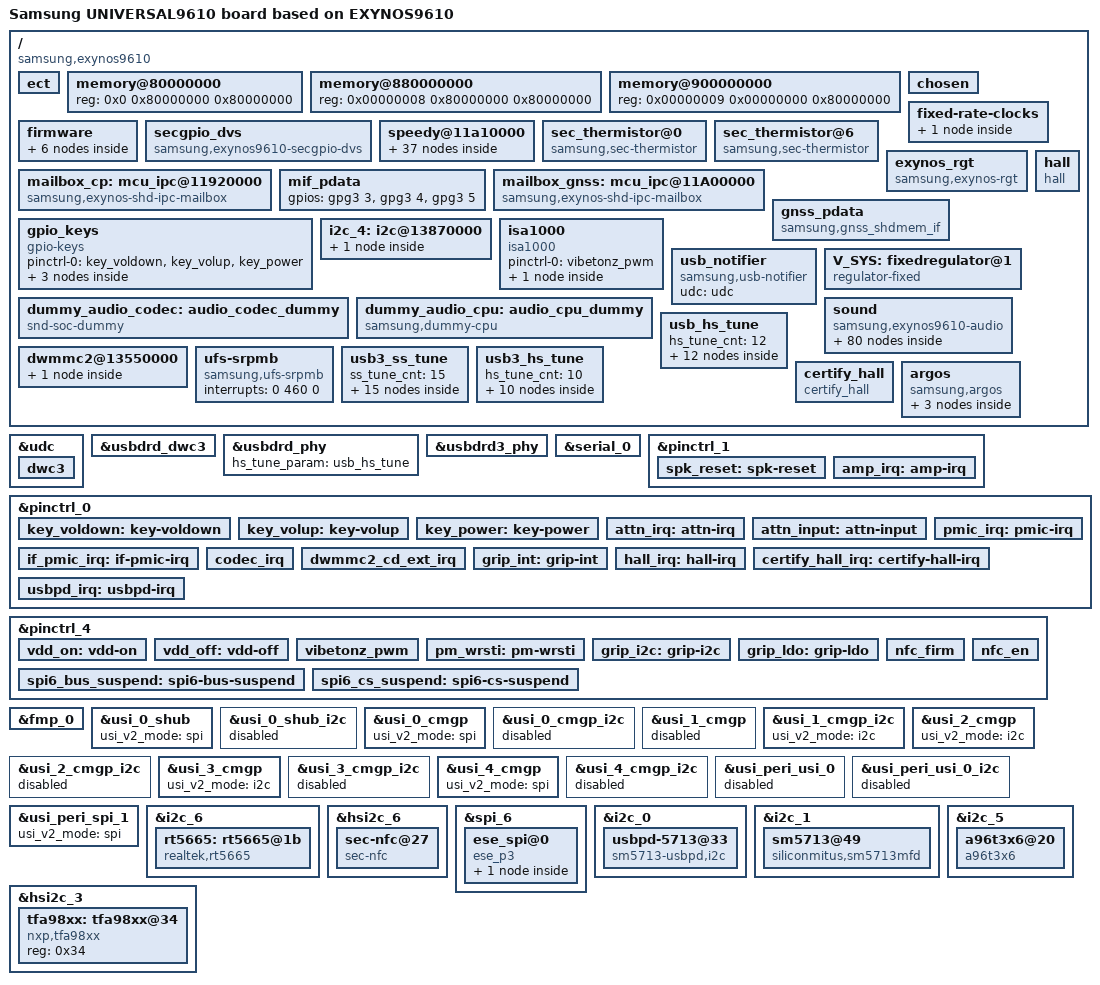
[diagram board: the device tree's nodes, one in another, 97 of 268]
/*
 * SAMSUNG EXYNOS9610 board device tree source
 *
 * Copyright (c) 2018 Samsung Electronics Co., Ltd.
 *		http://www.samsung.com
 *
 * This program is free software; you can redistribute it and/or modify
 * it under the terms of the GNU General Public License version 2 as
 * published by the Free Software Foundation.
 */

/dts-v1/;
/plugin/;

#include "battery_data_voguelte_common.dtsi"
#include <dt-bindings/camera/fimc_is.h>
#include <dt-bindings/clock/exynos9610.h>
#include "modem-s337ap-sipc-pdata.dtsi"
#include "display-lcd_vogue_common.dtsi"
#include "exynos9610-voguelte_camera.dtsi"
#include "exynos9610-inputbooster.dtsi"

/ {
	compatible = "samsung,exynos9610", "samsung,UNIVERSAL9610";

	fragment@model {
		target-path = "/";
		__overlay__ {
			#address-cells = <2>;
			#size-cells = <1>;
			model = "Samsung UNIVERSAL9610 board based on EXYNOS9610";

			ect {
				parameter_address = <0xA0000000>;
				parameter_size = <0x3A000>;
			};

			memory@80000000 {
				device_type = "memory";
				reg = <0x0 0x80000000 0x80000000>;
			};

			memory@880000000 {
				device_type = "memory";
				reg = <0x00000008 0x80000000 0x80000000>;
			};

			memory@900000000 {
				device_type = "memory";
				reg = <0x00000009 0x00000000 0x80000000>;
			};

			chosen {
				bootargs = "console=ram skip_initramfs rootwait ro init=/init clk_ignore_unused bcm_setup=0xffffff80f8e00000 androidboot.hardware=exynos9610 androidboot.selinux=permissive androidboot.debug_level=0x4948 firmware_class.path=/vendor/firmware ecd_setup=disable reserve-fimc=0xffffff80f9fe0000 pmic_info=0x3 epx_activate=true";
				linux,initrd-start = <0x84000000>;
				linux,initrd-end = <0x841FFFFF>;
			};

			fixed-rate-clocks {
				oscclk {
					compatible = "samsung,exynos9610-oscclk";
					clock-frequency = <26000000>;
				};
			};

			firmware {
				android {
					compatible = "android,firmware";
					vbmeta {
						compatible = "android,vbmeta";
						parts = "vbmeta,boot,system,vendor";
					};
					fstab {
						compatible = "android,fstab";
						system {
							compatible = "android,system";
							dev = "/dev/block/platform/13520000.ufs/by-name/system";
							type = "ext4";
							mnt_flags = "ro";
							fsmgr_flags = "wait, avb";
							status = "disabled";
						};
						vendor {
							compatible = "android,vendor";
							dev = "/dev/block/platform/13520000.ufs/by-name/vendor";
							type = "ext4";
							mnt_flags = "ro";
							fsmgr_flags = "wait, avb";
							status = "okay";
						};
						product {
							compatible = "android,product";
							dev = "/dev/block/platform/13520000.ufs/by-name/product";
							type = "ext4";
							mnt_flags = "ro";
							fsmgr_flags = "wait";
						};
					};
				};
			};

			secgpio_dvs {
				compatible = "samsung,exynos9610-secgpio-dvs";
				status = "okay";
			};

			speedy@11a10000 {
				#address-cells = <1>;
				#size-cells = <0>;
				status = "okay";
				s2mpu09mfd@00 {
					compatible = "samsung,s2mpu09mfd";
					acpm-ipc-channel = <2>;
					i2c-speedy-address;
					s2mpu09,wakeup = "enabled";
					s2mpu09,irq-gpio = <&gpa2 0 0>;
					reg = <0x00>;
					interrupts = <2 0 0>;
					interrupt-parent = <&gpa2>;
					pinctrl-names = "default";
					pinctrl-0 = <&pmic_irq &pm_wrsti>;
					/* RTC: wtsr/smpl */
					wtsr_en = "enabled"; /* enable */
					smpl_en = "enabled"; /* enable */
					wtsr_timer_val = <3>;	/* 1000ms */
					smpl_timer_val = <0>;	/* 100ms */
					check_jigon = <0>; /* do not check jigon */
					/* RTC: If it's first boot, reset rtc to 1/1/2019 12:00:00(Tue) */
					init_time,sec = <0>;
					init_time,min = <0>;
					init_time,hour = <12>;
					init_time,mday = <1>;
					init_time,mon = <0>;
					init_time,year = <119>;
					init_time,wday = <2>;

					regulators {
						b1_reg: BUCK1 {
							regulator-name = "vdd_mif";
							regulator-min-microvolt = <500000>;
							regulator-max-microvolt = <1100000>;
							regulator-always-on;
							regulator-ramp-delay = <12000>;
							regulator-initial-mode = <2>;
						};

						b2_reg: BUCK2 {
							regulator-name = "vdd_cpucl1";
							regulator-min-microvolt = <500000>;
							regulator-max-microvolt = <1300000>;
							regulator-always-on;
							regulator-ramp-delay = <12000>;
							regulator-initial-mode = <1>;
						};

						b3_reg: BUCK3 {
							regulator-name = "vdd_cpucl0";
							regulator-min-microvolt = <500000>;
							regulator-max-microvolt = <1300000>;
							regulator-always-on;
							regulator-ramp-delay = <12000>;
							regulator-initial-mode = <1>;
						};

						b4_reg: BUCK4{
							regulator-name = "vdd_int";
							regulator-min-microvolt = <500000>;
							regulator-max-microvolt = <1100000>;
							regulator-always-on;
							regulator-ramp-delay = <12000>;
							regulator-initial-mode = <2>;
						};

						b5_reg: BUCK5 {
							regulator-name = "vdd_g3d";
							regulator-min-microvolt = <500000>;
							regulator-max-microvolt = <1200000>;
							regulator-always-on;
							regulator-ramp-delay = <12000>;
							regulator-initial-mode = <2>;
						};

						b6_reg: BUCK6 {
							regulator-name = "vdd_cam_vipx";
							regulator-min-microvolt = <500000>;
							regulator-max-microvolt = <1300000>;
							regulator-always-on;
							regulator-ramp-delay = <12000>;
							regulator-initial-mode = <2>;
						};

						b7_reg: BUCK7 {
							regulator-name = "vdd2_mem";
							regulator-min-microvolt = <500000>;
							regulator-max-microvolt = <1300000>;
							regulator-always-on;
							regulator-ramp-delay = <12000>;
							regulator-initial-mode = <3>;
						};

						b8_reg: BUCK8 {
							regulator-name = "vdd_lldo";
							regulator-min-microvolt = <1200000>;
							regulator-max-microvolt = <1500000>;
							regulator-always-on;
							regulator-ramp-delay = <12000>;
							regulator-initial-mode = <3>;
						};

						b9_reg: BUCK9 {
							regulator-name = "vdd_mldo";
							regulator-min-microvolt = <1800000>;
							regulator-max-microvolt = <2100000>;
							regulator-always-on;
							regulator-ramp-delay = <12000>;
							regulator-initial-mode = <3>;
						};

						l1_reg: LDO1 {
							regulator-name = "vdd_ldo1";
							regulator-min-microvolt = <700000>;
							regulator-max-microvolt = <1300000>;
							regulator-always-on;
							regulator-ramp-delay = <12000>;
							regulator-initial-mode = <3>;
						};

						l2_reg: LDO2 {
							regulator-name = "vqmmc";
							regulator-min-microvolt = <1800000>;
							regulator-max-microvolt = <3375000>;
							regulator-ramp-delay = <12000>;
						};

						l3_reg: LDO3 {
							regulator-name = "vdd_ldo3";
							regulator-min-microvolt = <800000>;
							regulator-max-microvolt = <1950000>;
							regulator-always-on;
							regulator-ramp-delay = <12000>;
							regulator-initial-mode = <3>;
						};

						l4_reg: LDO4 {
							regulator-name = "vdd_ldo4";
							regulator-min-microvolt = <500000>;
							regulator-max-microvolt = <1100000>;
							regulator-always-on;
							regulator-ramp-delay = <12000>;
							regulator-initial-mode = <1>;
						};

						l5_reg: LDO5 {
							regulator-name = "vdd_ldo5";
							regulator-min-microvolt = <800000>;
							regulator-max-microvolt = <1300000>;
							regulator-always-on;
							regulator-ramp-delay = <12000>;
							regulator-initial-mode = <1>;
						};

						l6_reg: LDO6 {
							regulator-name = "vdd_ldo6";
							regulator-min-microvolt = <800000>;
							regulator-max-microvolt = <1300000>;
							regulator-always-on;
							regulator-ramp-delay = <12000>;
							regulator-initial-mode = <1>;
						};

						l7_reg: LDO7 {
							regulator-name = "vdd_ldo7";
							regulator-min-microvolt = <800000>;
							regulator-max-microvolt = <1950000>;
							regulator-always-on;
							regulator-ramp-delay = <12000>;
							regulator-initial-mode = <1>;
						};

						l8_reg: LDO8 {
							regulator-name = "vdd_ldo8";
							regulator-min-microvolt = <500000>;
							regulator-max-microvolt = <1300000>;
							regulator-always-on;
							regulator-ramp-delay = <12000>;
							regulator-initial-mode = <1>;
						};

						l9_reg: LDO9 {
							regulator-name = "vdd_ldo9";
							regulator-min-microvolt = <500000>;
							regulator-max-microvolt = <1300000>;
							regulator-always-on;
							regulator-ramp-delay = <12000>;
							regulator-initial-mode = <1>;
						};

						l10_reg: LDO10 {
							regulator-name = "vdd_ldo10";
							regulator-min-microvolt = <500000>;
							regulator-max-microvolt = <1300000>;
							regulator-always-on;
							regulator-ramp-delay = <12000>;
							regulator-initial-mode = <1>;
						};

						l11_reg: LDO11 {
							regulator-name = "vdd_ldo11";
							regulator-min-microvolt = <500000>;
							regulator-max-microvolt = <1300000>;
							regulator-always-on;
							regulator-ramp-delay = <12000>;
							regulator-initial-mode = <3>;
						};

						l12_reg: LDO12 {
							regulator-name = "vdd_ldo12";
							regulator-min-microvolt = <800000>;
							regulator-max-microvolt = <1300000>;
							regulator-ramp-delay = <12000>;
							regulator-initial-mode = <3>;
						};

						l13_reg: LDO13 {
							regulator-name = "vdd_ldo13";
							regulator-min-microvolt = <800000>;
							regulator-max-microvolt = <1950000>;
							regulator-ramp-delay = <12000>;
							regulator-initial-mode = <3>;
						};

						l14_reg: LDO14 {
							regulator-name = "vdd_ldo14";
							regulator-min-microvolt = <1800000>;
							regulator-max-microvolt = <3375000>;
							regulator-ramp-delay = <12000>;
							regulator-initial-mode = <3>;
						};

						l33_reg: LDO33 {
							regulator-name = "vdd_ldo33";
							regulator-min-microvolt = <800000>;
							regulator-max-microvolt = <1950000>;
							regulator-ramp-delay = <12000>;
						};

						l34_reg: LDO34 {
							regulator-name = "vdd_ldo34";
							regulator-min-microvolt = <1800000>;
							regulator-max-microvolt = <3375000>;
							regulator-ramp-delay = <12000>;
						};

						l35_reg: LDO35 {
							regulator-name = "vmmc";
							regulator-min-microvolt = <1800000>;
							regulator-max-microvolt = <3375000>;
							regulator-ramp-delay = <12000>;
						};

						l36_reg: LDO36 {
							regulator-name = "vdd_ldo36";
							regulator-min-microvolt = <500000>;
							regulator-max-microvolt = <1300000>;
							regulator-always-on;
							regulator-ramp-delay = <12000>;
							regulator-initial-mode = <1>;
						};

						l37_reg: LDO37 {
							regulator-name = "VDD_NFC_1P8";
							regulator-min-microvolt = <1800000>;
							regulator-max-microvolt = <1800000>;
							regulator-ramp-delay = <12000>;
							regulator-initial-mode = <2>;
						};

						l38_reg: LDO38 {
							regulator-name = "vdd_ldo38";
							regulator-min-microvolt = <2800000>;
							regulator-max-microvolt = <2800000>;
							regulator-ramp-delay = <12000>;
						};

						l39_reg: LDO39 {
							regulator-name = "vdd_ldo39";
							regulator-min-microvolt = <1800000>;
							regulator-max-microvolt = <1800000>;
							regulator-initial-mode = <3>;
							regulator-always-on;
						};

						l40_reg: LDO40 {
							regulator-name = "vdd_ldo40";
							regulator-min-microvolt = <3300000>;
							regulator-max-microvolt = <3300000>;
							regulator-initial-mode = <3>;
							regulator-always-on;
						};

						l41_reg: LDO41 {
							regulator-name = "vdd_ldo41";
							regulator-min-microvolt = <1800000>;
							regulator-max-microvolt = <3375000>;
							regulator-ramp-delay = <12000>;
						};

						l42_reg: LDO42 {
							regulator-name = "vdd_ldo42";
							regulator-min-microvolt = <800000>;
							regulator-max-microvolt = <1950000>;
							regulator-ramp-delay = <12000>;
						};

						l43_reg: LDO43 {
							regulator-name = "vdd_ldo43";
							regulator-min-microvolt = <500000>;
							regulator-max-microvolt = <1300000>;
							regulator-always-on;
							regulator-ramp-delay = <12000>;
							regulator-initial-mode = <1>;
						};

						l44_reg: LDO44 {
							regulator-name = "vdd_ldo44";
							regulator-min-microvolt = <800000>;
							regulator-max-microvolt = <1300000>;
							regulator-ramp-delay = <12000>;
						};
					};
				};
			};

			sec_thermistor@0 {
				compatible = "samsung,sec-thermistor";
				status = "okay";
				thermistor_name = "sec-ap-thermistor";
				id = <0>;

				adc_array = <275 324 380 450 528 619 729 856 1003 1161
					  1345 1545 1766 1980 2222 2457 2685 2901 3102 3279
					  3426 3551 3659>;
				temp_array = <900 850 800 750 700 650 600 550 500 450
					  400 350 300 250 200 150 100 50 0 (-50)
					  (-100) (-150) (-200)>;

				io-channels = <&exynos_adc 0>;
				io-channel-names = "adc-ap-temp";
				io-channel-ranges;
			};

			sec_thermistor@6 {
				compatible = "samsung,sec-thermistor";
				status = "okay";
				thermistor_name = "sec-wf-thermistor";
				id = <1>;

				adc_array = <275 324 380 450 528 619 729 856 1003 1161
					  1345 1545 1766 1980 2222 2457 2685 2901 3102 3279
					  3426 3551 3659>;
				temp_array = <900 850 800 750 700 650 600 550 500 450
					  400 350 300 250 200 150 100 50 0 (-50)
					  (-100) (-150) (-200)>;

				io-channels = <&exynos_adc 6>;
				io-channel-names = "adc-wf-temp";
				io-channel-ranges;
			};

			exynos_rgt {
				compatible = "samsung,exynos-rgt";
			};

			mailbox_cp: mcu_ipc@11920000 {
				compatible = "samsung,exynos-shd-ipc-mailbox";
				reg = <0x0 0x11920000 0x180>;
				mcu,name = "mcu_ipc_cp";
				mcu,id = <0>;
				interrupts = <0 40 0 >;
				mcu,irq_affinity_mask = <3>;
			};

			mif_pdata {
				/* GPIOs for HW REV */
				/* XGPIO27-AP_REV0, XGPIO28-AP_REV1, XGPIO29-AP_REV2 */
				gpios = <&gpg3 3 0>, <&gpg3 4 0>, <&gpg3 5 0>;
				pinctrl-names = "default";
			};

			mailbox_gnss: mcu_ipc@11A00000 {
				compatible = "samsung,exynos-shd-ipc-mailbox";
				reg = <0x0 0x11A00000 0x180>;
				mcu,name = "mcu_ipc_gnss";
				mcu,id = <1>;
				interrupts = <0 43 0>; /* INTREQ__MAILBOX_GNSS2AP */
			};

			gnss_pdata {
				status = "okay";

				compatible = "samsung,gnss_shdmem_if";
				shmem,name = "KEPLER";
				shmem,device_node_name = "gnss_ipc";

				/* INTREQ__ALIVE_GNSS_ACTIVE, INTREQ__GNSS2AP_WDOG_RESET, INTREQ__GNSS2AP_WAKEUP, INTREQ__GNSS2AP */
				interrupts = <0 27 0>, <0 81 0>, <0 80 0>, <0 79 0>;
				interrupt-names = "ACTIVE", "WATCHDOG", "WAKEUP", "REQ_INIT";

				memory-region = <&gnss_reserved>;
				mbox_info = <&mailbox_gnss>;

				mbx,int_ap2gnss_bcmd = <0>;
				mbx,int_ap2gnss_req_fault_info = <1>;
				mbx,int_ap2gnss_ipc_msg = <2>;
				mbx,int_ap2gnss_ack_wake_set = <3>;
				mbx,int_ap2gnss_ack_wake_clr = <4>;

				mbx,irq_gnss2ap_bcmd = <0>;
				mbx,irq_gnss2ap_rsp_fault_info = <1>;
				mbx,irq_gnss2ap_ipc_msg = <2>;
				mbx,irq_gnss2ap_req_wake_clr = <4>;

				mbx,reg_bcmd_ctrl = <0>, <1>, <2>, <3>;

				reg_rx_ipc_msg = <1 5>;
				reg_tx_ipc_msg = <1 4>;
				reg_rx_head = <1 3>;
				reg_rx_tail = <1 2>;
				reg_tx_head = <1 1>;
				reg_tx_tail = <1 0>;
				fault_info = <1 0x200000 0x180000>;

				shmem,ipc_offset = <0x380000>;
				shmem,ipc_size = <0x80000>;
				shmem,ipc_reg_cnt = <32>;
			};

			gpio_keys {
				#address-cells = <1>;
				#size-cells = <0>;
				compatible = "gpio-keys";
				status = "okay";
				pinctrl-names = "default";
				pinctrl-0 = <&key_voldown &key_volup &key_power>;
				button@1 {
					label = "gpio-keys: KEY_VOLUMEDOWN";
					linux,code = <114>;
					gpios = <&gpa1 6 0xf>;
				};
				button@2 {
					label = "gpio-keys: KEY_VOLUMEUP";
					linux,code = <115>;
					gpios = <&gpa1 5 0xf>;
				};
				button@3 {
					label = "gpio-keys: KEY_POWER";
					linux,code = <116>;
					gpios = <&gpa1 7 0xf>;
					gpio-key,wakeup = <1>;
				};
			};

			i2c_4:i2c@13870000 {
				#address-cells = <1>;
				#size-cells = <0>;
				status = "okay";
				samsung,i2c-sda-delay = <100>;
				samsung,i2c-max-bus-freq = <400000>;
				touchscreen@48 {
					compatible = "sec,sec_ts";
					reg = <0x48>;
					pinctrl-names = "on_state", "off_state";
					pinctrl-0 = <&attn_irq &vdd_on>;
					pinctrl-1 = <&attn_input &vdd_off>;
					sec,irq_gpio = <&gpa0 0 0>;
					sec,irq_type = <8200>;
					sec,num_lines = <28 16>;        /* rx tx */
					sec,max_coords = <3840 2160>;   /* x y */
					sec,use_ic_info = <1>;
					sec,grip_area = <512>;
					//sec,regulator_dvdd = "vdd3";
					//sec,regulator_avdd = "vdd5";
					sec,project_name = "lassen", "universal7885";
					status = "okay";
				};
			};
			isa1000 {
				compatible = "isa1000";
				pinctrl-names = "default";
				pinctrl-0 = <&vibetonz_pwm>;
				isa1000_pdata {
					status = "okay";
					isa1000,max_timeout = <10000>;
					isa1000,pwm_use = <1>;
					isa1000,duty = <34290>;
					isa1000,period = <38100>;
					isa1000,pwm_id = <0>;
					isa1000,gpio_en = <&gpa2 1 0>;
					isa1000,regulator_name = "VDD_MOT_3.3";
				};
			};
			usb_notifier {
				compatible = "samsung,usb-notifier";
				udc = <&udc>;
			};

			V_SYS: fixedregulator@1 {
				compatible = "regulator-fixed";
				regulator-name = "V_SYS";
				regulator-min-microvolt = <4200000>;
				regulator-max-microvolt = <4200000>;
				regulator-boot-on;
				regulator-always-on;
			};

			dummy_audio_codec: audio_codec_dummy {
				status = "okay";
				compatible = "snd-soc-dummy";
			};

			dummy_audio_cpu: audio_cpu_dummy {
				compatible = "samsung,dummy-cpu";
				status = "okay";
			};

			sound {
				status = "okay";
				compatible = "samsung,exynos9610-audio";

				clock-names = "xclkout";
				clocks = <&clock OSC_AUD>;
				pinctrl-names = "default";
				pinctrl-0 = <&xclkout0>;

				samsung,routing =
					"IN1P", "HEADSETMIC",
					"IN1N", "HEADSETMIC",
					"IN2P", "MAINMIC",
					"IN2P", "SUBMIC",
					"HEADPHONE", "HPOL",
					"HEADPHONE", "HPOR",
					"VOUTPUT", "ABOX UAIF0 Playback",
					"SPEAKER", "ABOX UAIF2 Playback",
					"VOUTPUTCALL", "ABOX SIFS0 Playback",
					"BLUETOOTH SPK", "ABOX SIFS2 Playback",
					"ABOX SIFS2 Capture", "BLUETOOTH MIC",
					"ABOX SIFS0 Capture", "VINPUTCALL";

				samsung,codec = <&abox &abox_uaif_0 &abox_uaif_1 &abox_uaif_2
					&abox_uaif_4 &abox_dsif &abox_spdy>;
				samsung,prefix = "ABOX", "ABOX", "ABOX", "ABOX",
					"ABOX", "ABOX", "ABOX";
				samsung,aux = <&abox_effect &abox_bt>;

				rdma@0 {
					cpu {
						sound-dai = <&abox 0>;
					};
					platform {
						sound-dai = <&abox_rdma_0>;
					};
					codec {
						sound-dai = <&dummy_audio_codec>;
					};
				};
				rdma@1 {
					cpu {
						sound-dai = <&abox 1>;
					};
					platform {
						sound-dai = <&abox_rdma_1>;
					};
					codec {
						sound-dai = <&dummy_audio_codec>;
					};
				};
				rdma@2 {
					cpu {
						sound-dai = <&abox 2>;
					};
					platform {
						sound-dai = <&abox_rdma_2>;
					};
					codec {
						sound-dai = <&dummy_audio_codec>;
					};
				};
				rdma@3 {
					cpu {
						sound-dai = <&abox 3>;
					};
					platform {
						sound-dai = <&abox_rdma_3>;
					};
					codec {
						sound-dai = <&dummy_audio_codec>;
					};
				};
				rdma@4 {
					cpu {
						sound-dai = <&abox 4>;
					};
					platform {
						sound-dai = <&abox_rdma_4>;
					};
					codec {
						sound-dai = <&dummy_audio_codec>;
					};
				};
				rdma@5 {
					cpu {
						sound-dai = <&abox 5>;
					};
					platform {
						sound-dai = <&abox_rdma_5>;
					};
					codec {
						sound-dai = <&dummy_audio_codec>;
					};
				};
				rdma@6 {
					cpu {
						sound-dai = <&abox 6>;
					};
					platform {
						sound-dai = <&abox_rdma_6>;
					};
					codec {
						sound-dai = <&dummy_audio_codec>;
					};
				};
				rdma@7 {
					cpu {
						sound-dai = <&abox 7>;
					};
					platform {
						sound-dai = <&abox_rdma_7>;
					};
					codec {
						sound-dai = <&dummy_audio_codec>;
					};
				};
				wdma@0 {
					cpu {
						sound-dai = <&abox 8>;
					};
					platform {
						sound-dai = <&abox_wdma_0>;
					};
					codec {
						sound-dai = <&dummy_audio_codec>;
					};
				};
				wdma@1 {
					cpu {
						sound-dai = <&abox 9>;
					};
					platform {
						sound-dai = <&abox_wdma_1>;
					};
					codec {
						sound-dai = <&dummy_audio_codec>;
					};
				};
				wdma@2 {
					cpu {
						sound-dai = <&abox 10>;
					};
					platform {
						sound-dai = <&abox_wdma_2>;
					};
					codec {
						sound-dai = <&dummy_audio_codec>;
					};
				};
				wdma@3 {
					cpu {
						sound-dai = <&abox 11>;
					};
					platform {
						sound-dai = <&abox_wdma_3>;
					};
					codec {
						sound-dai = <&dummy_audio_codec>;
					};
				};
				wdma@4 {
					cpu {
						sound-dai = <&abox 12>;
					};
					platform {
						sound-dai = <&abox_wdma_4>;
					};
					codec {
						sound-dai = <&dummy_audio_codec>;
					};
				};
		/** ToDo: enable dp_audio link after enabling DP Audio
		 *		dp_audio@0 {
		 *			cpu {
		 *				sound-dai = <&dummy_audio_cpu>;
		 *			};
		 *			codec {
		 *				sound-dai = <&dummy_audio_codec>;
		 *			};
		 *		};
		 */
				uaif@0 {
					format = "i2s";
					cpu {
						sound-dai = <&abox_uaif_0>;
					};
					codec {
						sound-dai = <&rt5665 0>;
					};
				};
				uaif@1 {
					format = "i2s";
					cpu {
						sound-dai = <&abox_uaif_1>;
					};
					codec {
						sound-dai = <&dummy_audio_codec>;
					};
				};
				uaif@2 {
					format = "i2s";
					cpu {
						sound-dai = <&abox_uaif_2>;
					};
					platform {
						sound-dai = <&abox_synchronized_ipc 0>;
					};
					codec {
						sound-dai = <&tfa98xx 0>;
					};
				};
				uaif@4 {
					format = "i2s";
					bitclock-master;
					frame-master;
					cpu {
						sound-dai = <&abox_uaif_4>;
					};
					codec {
						sound-dai = <&dummy_audio_codec>;
					};
				};
				dsif@0 {
					format = "pdm";
					cpu {
						sound-dai = <&abox_dsif>;
					};
					codec {
						sound-dai = <&dummy_audio_codec>;
					};
				};
				spdy@0 {
					cpu {
						sound-dai = <&abox_spdy>;
					};
					codec {
						sound-dai = <&dummy_audio_codec>;
					};
				};
				sifs0@0 {
					cpu {
						sound-dai = <&abox 13>;
					};
					codec {
						sound-dai = <&dummy_audio_codec>;
					};
				};
				sifs1@0 {
					cpu {
						sound-dai = <&abox 14>;
					};
					codec {
						sound-dai = <&dummy_audio_codec>;
					};
				};
				sifs2@0 {
					cpu {
						sound-dai = <&abox 15>;
					};
					codec {
						sound-dai = <&dummy_audio_codec>;
					};
				};
			};

			dwmmc2@13550000 {
				status = "okay";
				num-slots = <1>;
				supports-4bit;
				supports-cmd23;
				supports-erase;
				supports-highspeed;
				sd-uhs-sdr50;
				sd-uhs-sdr104;
				card-detect-gpio;
				bypass-for-allpass;
				card-init-hwacg-ctrl;
				skip-init-mmc-scan;
				qos-dvfs-int-level = <533000>;
				qos-dvfs-mif-level = <676000>;
				fifo-depth = <0x40>;
				desc-size = <4>;
				card-detect-delay = <200>;
				data-timeout = <200>;
				hto-timeout = <80>;
				samsung,dw-mshc-ciu-div = <3>;
				clock-frequency = <800000000>;
				ssc-rate = <3>;
				samsung,dw-mshc-sdr-timing = <3 0 2 0>;
				samsung,dw-mshc-ddr-timing = <3 0 2 1>;
				samsung,dw-mshc-sdr50-timing = <3 0 4 2>;
				samsung,dw-mshc-sdr104-timing = <3 0 3 0>;

				num-ref-clks = <9>;
				ciu_clkin = <25 50 50 25 50 100 200 50 50>;

				/* Swapping clock drive strength */
				clk-drive-number = <4>;
				pinctrl-names = "default",
					"fast-slew-rate-1x",
					"fast-slew-rate-2x",
					"fast-slew-rate-3x",
					"fast-slew-rate-4x";
				pinctrl-0 = <&sd2_clk &sd2_cmd &sd2_bus1 &sd2_bus4 &dwmmc2_cd_ext_irq>;
				pinctrl-1 = <&sd2_clk_fast_slew_rate_1x>;
				pinctrl-2 = <&sd2_clk_fast_slew_rate_2x>;
				pinctrl-3 = <&sd2_clk_fast_slew_rate_3x>;
				pinctrl-4 = <&sd2_clk_fast_slew_rate_4x>;

				card-detect = <&gpa2 6 0xf>;
				sec-sd-slot-type = <2>; /* Hybrid Tray SD slot */
				#address-cells = <1>;
				#size-cells = <0>;

				slot@0 {
					reg = <0>;
					bus-width = <4>;
					disable-wp;
				};
			};

			usb_hs_tune:usb_hs_tune {
				hs_tune_cnt = <12>;

				/* value = <device host> */
				hs_tune1 {
					tune_name = "tx_vref";
					tune_value = <0xf 0xf>;
				};

				hs_tune2 {
					tune_name = "tx_pre_emp";
					tune_value = <0x3 0x3>;
				};

				hs_tune3 {
					tune_name = "tx_pre_emp_plus";
					tune_value = <0x0 0x0>;
				};

				hs_tune4 {
					tune_name = "tx_res";
					tune_value = <0x3 0x3>;
				};

				hs_tune5 {
					tune_name = "tx_rise";
					tune_value = <0x3 0x3>;
				};

				hs_tune6 {
					tune_name = "tx_hsxv";
					tune_value = <0x3 0x3>;
				};

				hs_tune7 {
					tune_name = "tx_fsls";
					tune_value = <0x3 0x3>;
				};

				hs_tune8 {
					tune_name = "rx_sqrx";
					tune_value = <0x7 0x7>;
				};

				hs_tune9 {
					tune_name = "compdis";
					tune_value = <0x7 0x7>;
				};

				hs_tune10 {
					tune_name = "otg";
					tune_value = <0x2 0x2>;
				};

				hs_tune11 {
				/* true : 1, false: 0 */
				/* <enable_user_imp user_imp_value> */
					tune_name = "enable_user_imp";
					tune_value = <0x0 0x0>;
				};

				hs_tune12 {
				/* PHY clk : 1 , FREE clk : 0 */
					tune_name = "is_phyclock";
					tune_value = <0x1 0x1>;
				};
			};

			/* Secure RPMB */
			ufs-srpmb {
				compatible = "samsung,ufs-srpmb";
				interrupts = <0 460 0>;
			};

			usb3_ss_tune:usb3_ss_tune {
				ss_tune_cnt = <15>;

				/* value = <device host> */
				ss_tune1 {
					tune_name = "tx0_term_offset";
					tune_value = <0x0 0x0>;
				};

				ss_tune2 {
					tune_name = "pcs_tx_swing_full";
					tune_value = <0x7f 0x7f>;
				};

				ss_tune3 {
					tune_name = "pcs_tx_deemph_6db";
					tune_value = <0x1c 0x1c>;
				};

				ss_tune4 {
					tune_name = "pcs_tx_deemph_3p5db";
					tune_value = <0x1c 0x1c>;
				};

				ss_tune5 {
					tune_name = "tx_vboost_lvl_sstx";
					tune_value = <0x7 0x7>;
				};

				ss_tune6 {
					tune_name = "tx_vboost_lvl";
					tune_value = <0x4 0x4>;
				};

				ss_tune7 {
					tune_name = "los_level";
					tune_value = <0x9 0x9>;
				};

				ss_tune8 {
					tune_name = "los_bias";
					tune_value = <0x5 0x5>;
				};

				ss_tune9 {
					tune_name = "pcs_rx_los_mask_val";
					tune_value = <0x104 0x104>;
				};

				ss_tune10 {
					tune_name = "tx_eye_height_cntl_en";
					tune_value = <0x1 0x1>;
				};

				ss_tune11 {
					tune_name = "pipe_tx_deemph_update_delay";
					tune_value = <0x2 0x2>;
				};

				ss_tune12 {
					tune_name = "pcs_tx_swing_full_sstx";
					tune_value = <0x7f 0x7f>;
				};
				ss_tune13 {
					tune_name = "rx_eq_fix_val";
					tune_value = <0x2 0x2>;
				};

				ss_tune14 {
					tune_name = "rx_decode_mode";
					tune_value = <0x1 0x1>;
				};

				ss_tune15 {
					tune_name = "decrese_ss_tx_imp";
					tune_value = <0x1 0x1>;
				};
			};

			usb3_hs_tune:usb3_hs_tune {
				hs_tune_cnt = <10>;

				/* value = <device host> */
				hs_tune1 {
					tune_name = "tx_pre_emp";
					tune_value = <0x3 0x3>;
				};

				hs_tune2 {
					tune_name = "tx_pre_emp_plus";
					tune_value = <0x0 0x0>;
				};

				hs_tune3 {
					tune_name = "tx_vref";
					tune_value = <0x7 0x7>;
				};

				hs_tune4 {
					tune_name = "rx_sqrx";
					tune_value = <0x7 0x7>;
				};

				hs_tune5 {
					tune_name = "tx_rise";
					tune_value = <0x3 0x3>;
				};

				hs_tune6 {
					tune_name = "compdis";
					tune_value = <0x7 0x7>;
				};

				hs_tune7 {
					tune_name = "tx_hsxv";
					tune_value = <0x3 0x3>;
				};

				hs_tune8 {
					tune_name = "tx_fsls";
					tune_value = <0x3 0x3>;
				};

				hs_tune9 {
					tune_name = "tx_res";
					tune_value = <0x3 0x3>;
				};

				hs_tune10 {
					tune_name = "utim_clk";
					tune_value = <0x1 0x1>;
				};
			};
			
			hall {
				status = "okay";
				compatible = "hall";
				pinctrl-names = "default";
				pinctrl-0 = <&hall_irq>;
				hall,gpio_flip_cover = <&gpa0 3 0>;
			};

			certify_hall {
				status = "okay";
				compatible = "certify_hall";
				pinctrl-names = "default";
				pinctrl-0 = <&certify_hall_irq>;
				certify_hall,gpio_certify_cover = <&gpa0 4 0>;
			};

			argos {
				compatible = "samsung,argos";
				#address-cells = <1>;
				/*  The device number should be assigned for each device, e.g. "boot_device@1" and "boot_device@2".
				 * Duplicated number is not allowed. Please refer the below example.
				 */

				/* Table Format should be
				 * <Throughput(Mbps) BIG_min BIG_max MID_min MID_max LIT_min Little_max MIF INT Task IRQ HMP_boost>
				 * BIG_min : Big Core's minimum frequency lock. 0 means not set,
				 * BIG_max : Big Core's maximum frequency lock. 0 means not set,
				 * LIT_min : Little Core's minimum frequency lock. 0 means not set,
				 * LIT_max : Little Core's maximum frequency lock. 0 means not set,
				 * MIF : MIF frequency lock. 0 means not set,
				 * INT : INT frequency lock. 0 means not set,
				 * Task : 1 - Set task affinity lock.
				 *	0 - Not set or unlock,
				 *		Task affinity should be predefined driver's code.
				 * IRQ : 1 - Set irq affinity lock.
				 *       0 - Not set or unlock,
				 *		Task affinity should be predefined driver's code.
				 * HMP_boots : 1 - Increase hmp boosting count
				 *             0 - Decrease hmp boosting count
				 */

				/*
				 * boot_device@9 {
				 *	net_boost,label="WIFI RX";
				 *	net_boost,node="wlan0";
				 *	net_boost,table_size = <4>;
				 *	net_boost,table= <
				 *		5  2002000 0 1690000 0 0 0 0 0 0
				 *		10 2002000 0 1690000 0 0 0 0 0 0
				 *		20 2002000 0 1690000 0 845000 400000 1 1 1
				 *		30 2002000 0 1690000 0 1352000 533000 1 1 1
				 *		>;
				 * };
				 */

				boot_device@1 {
					net_boost,label="IPC";
					net_boost,node="rmnet0 rmnet1 rmnet2 rmnet3 rmnet4 rmnet5 rmnet6 rmnet7 umts_dm0";
					net_boost,table_size = <4>;
					net_boost,table= <
						50 0 0 910000 0 845000 0 0 0 0
						100 0 0 1326000 0 1014000 0 0 0 0
						200 0 0 1534000 0 1352000 0 0 0 0
						300 16640000 0 1456000 0 1539000 0 0 0 0
						>;
				};

				boot_device@2 {
					net_boost,label="CLAT";
					net_boost,node="clat clat4 v4-rmnet0 v4-rmnet1 v4-rmnet2 v4-rmnet3 v4-rmnet4 v4-rmnet5 v4-rmnet6 v4-rmnet7";
					net_boost,table_size = <3>;
					net_boost,table= <
						100 1040000 0 0 0 0 0 1014000 0 0 0 0
						150 1248000 0 0 0 0 0 1352000 0 0 0 0
						200 1456000 0 0 0 0 0 2093000 0 0 0 0
						>;
				};

				boot_device@3 {
					net_boost,label="USB";
					net_boost,node="rndis0";
					net_boost,table_size = <1>;
					net_boost,table= < 0 0 0 0 0 0 0 0 1 0 >;
				};
			};
		};
	};
};

&udc {
	status = "okay";
	dwc3 {
		dr_mode = "otg";
		maximum-speed = "super-speed";
	};
};

&usbdrd_dwc3 {
	dr_mode = "otg";
	maximum-speed = "super-speed";

	ldo-names = "vdd_ldo12", "vdd_ldo13", "vdd_ldo14";
};

&usbdrd_phy {
	status = "okay";
	hs_tune_param = <&usb_hs_tune>;
};

&usbdrd3_phy {
	status = "okay";
	hs_tune_param = <&usb3_hs_tune>;
	ss_tune_param = <&usb3_ss_tune>;
};

&serial_0 {
	status = "okay";
};

&pinctrl_1 {
	spk_reset: spk-reset {
		samsung,pins ="gpm24-0";
		samsung,pin-pud = <0>;
	};
	amp_irq: amp-irq {
		samsung,pins ="gpm25-0";
		samsung,pin-function = <0xf>;
		samsung,pin-pud = <0>;
	};
};

&pinctrl_0 {
	key_voldown: key-voldown {
		samsung,pins = "gpa1-6";
		samsung,pin-function = <0xf>;
		samsung,pin-pud = <0>;
		samsung,pin-drv = <0>;
	};

	key_volup: key-volup {
		samsung,pins = "gpa1-5";
		samsung,pin-function = <0xf>;
		samsung,pin-pud = <0>;
		samsung,pin-drv = <0>;
	};

	key_power: key-power {
		samsung,pins = "gpa1-7";
		samsung,pin-function = <0xf>;
		samsung,pin-pud = <0>;
		samsung,pin-drv = <0>;
	};

	attn_irq: attn-irq {
		samsung,pins = "gpa0-0";
		samsung,pin-function = <0xf>;
		samsung,pin-pud = <0>;
		samsung,pin-drv = <0>;
	};

	attn_input: attn-input {
		samsung,pins = "gpa0-0";
		samsung,pin-function = <0>;
		samsung,pin-pud = <1>;
	};

	if_pmic_irq: if-pmic-irq {
		samsung,pins = "gpa2-2";
		samsung,pin-function = <0>;
		samsung,pin-pud = <0>;
		samsung,pin-drv = <0>;
	};

	pmic_irq: pmic-irq {
		samsung,pins = "gpa2-0";
		samsung,pin-pud = <3>;
		samsung,pin-drv = <3>;
	};

	codec_irq: codec_irq {
		samsung,pins ="gpa1-2";
		samsung,pin-function = <0xf>;
		samsung,pin-pud = <0>;
	};

	dwmmc2_cd_ext_irq: dwmmc2_cd_ext_irq {
		samsung,pins = "gpa2-6";
		samsung,pin-function = <0xf>;
		samsung,pin-pud = <0>;
		samsung,pin-drv = <3>;
	};

	grip_int: grip-int {
		samsung,pins = "gpa2-7";
		samsung,pin-function = <0xf>;
		samsung,pin-pud = <0>;
	};

	hall_irq: hall-irq {
		samsung,pins = "gpa0-3";
		samsung,pin-function = <0xf>;
		samsung,pin-pud = <0>;
		samsung,pin-drv = <0>;
	};

	certify_hall_irq: certify-hall-irq {
		samsung,pins = "gpa0-4";
		samsung,pin-function = <0xf>;
		samsung,pin-pud = <0>;
		samsung,pin-drv = <0>;
	};

	usbpd_irq: usbpd-irq {
		samsung,pins = "gpa2-3";
		samsung,pin-function = <0x0f>;
		samsung,pin-pud = <0>;
		samsung,pin-drv = <0>;
	};
};

&pinctrl_4 {
	vdd_on: vdd-on {
		samsung,pins = "gpg3-1";
		samsung,pin-function = <1>;
		samsung,pin-val = <1>;
		samsung,pin-pud = <0>;
	};

	vdd_off: vdd-off {
		samsung,pins = "gpg3-1";
		samsung,pin-function = <0>;
		samsung,pin-val = <0>;
		samsung,pin-pud = <1>;
	};

	vibetonz_pwm: vibetonz_pwm {
		samsung,pins = "gpg4-1";
		samsung,pin-function = <2>;
		samsung,pin-pud = <1>;
		samsung,pin-drv = <0>;
	};
	
	/* Warm reset information from AP */
	pm_wrsti: pm-wrsti {
		samsung,pins = "gpg0-7";
		samsung,pin-con-pdn = <3>;
	};

	grip_i2c: grip-i2c {
		samsung,pins = "gpp1-2", "gpp1-3";
		samsung,pin-function = <2>;
		samsung,pin-pud = <0>;
	};

	grip_ldo: grip-ldo {
		samsung,pins = "gpg2-1";
		samsung,pin-function = <1>;
		samsung,pin-pud = <0>;
	};
};

&fmp_0 {
	 exynos,block-type = "sda";
	 exynos,fips-block_offset = <5>;
};

/* USI_0_SHUB */
&usi_0_shub {
	usi_v2_mode = "spi";
	status = "okay";
};

/* USI_SHUB_0_I2C */
&usi_0_shub_i2c {
	/*	usi_v2_mode = "i2c" or "spi" or "uart"	*/
	status = "disabled";
};

/* USI_0_CMGP */
&usi_0_cmgp {
	/*	usi_v2_mode = "i2c" or "spi" or "uart"	*/
	usi_v2_mode = "spi";
	status = "okay";
};

/* USI_0_CMGP_I2C */
&usi_0_cmgp_i2c {
	/*	usi_v2_mode = "i2c" or "spi" or "uart"	*/
	status = "disabled";
};

/* USI_1_CMGP */
&usi_1_cmgp {
	/*	usi_v2_mode = "i2c" or "spi" or "uart"	*/
	status = "disabled";
};

/* USI_1_CMGP_I2C */
&usi_1_cmgp_i2c {
	usi_v2_mode = "i2c";
	status = "okay";
};

/* USI_2_CMGP */
&usi_2_cmgp {
	/*	usi_v2_mode = "i2c" or "spi" or "uart"	*/
	usi_v2_mode = "i2c";
	status = "okay";
};

/* USI_2_CMGP_I2C */
&usi_2_cmgp_i2c {
	/*	usi_v2_mode = "i2c" or "spi" or "uart"	*/
	status = "disabled";
};

/* USI_3_CMGP */
&usi_3_cmgp {
	usi_v2_mode = "i2c";
	status = "okay";
};

/* USI_3_CMGP_I2C */
&usi_3_cmgp_i2c {
	/*	usi_v2_mode = "i2c" or "spi" or "uart"	*/
	status = "disabled";
};

/* USI_4_CMGP */
&usi_4_cmgp {
	usi_v2_mode = "spi";
	status = "okay";
};

/* USI_4_CMGP_I2C */
&usi_4_cmgp_i2c {
	status = "disabled";
};

/* USI_PERI_USI_0 */
&usi_peri_usi_0 {
	/*	usi_v2_mode = "i2c" or "spi" or "uart"	*/
	status = "disabled";
};

/* USI_PERI_USI_0_I2C */
&usi_peri_usi_0_i2c {
	/*	usi_v2_mode = "i2c" or "spi" or "uart"	*/
	status = "disabled";
};

/* USI_PERI_SPI_1 */
&usi_peri_spi_1 {
	usi_v2_mode = "spi";
	status = "okay";
};

&i2c_6 {
	#address-cells = <1>;
	#size-cells = <0>;
	status = "okay";
	rt5665: rt5665@1b {
		compatible = "realtek,rt5665";
		reg = <0x1b>;
		pinctrl-names = "default";
		pinctrl-0 = <&codec_irq>;
		interrupt-parent = <&gpa1>;
		interrupts = <2 0 0>;
		#sound-dai-cells = <1>;
		realtek,in1-differential;
		realtek,in3-differential;
		realtek,in4-differential;
		realtek,jd-src = <2>;
		realtek,dmic2-data-pin =<2>;
		realtek,sar-hs-type = <614>;
		realtek,sar-pb-vth0 = <110>;
		realtek,sar-pb-vth1 = <135>;
		realtek,sar-pb-vth2 = <255>;
		realtek,sar-pb-vth3 = <700>;
		imp_table = <
			/*min max gain bias*/
			0x0000 0x000d 0 6 // 8 ohm
			0x000e 0x0019 0 6 // 16 ohm
			0x001a 0x0035 0 6 // 32 ohm
			0x0036 0x0067 0 1 // 64 ohm
			0x0068 0xffff 0 1 // > 100 ohm
		>;

		realtek,regulator_1v8 = <&l39_reg>;
		realtek,regulator_3v3 = <&l40_reg>;
	};
};

&pinctrl_4 {
	nfc_firm: nfc_firm {
		samsung,pins = "gpg1-0";
		samsung,pin-function = <1>;
		samsung,pin-pud = <0>;
		samsung,pin-val = <0>;
		samsung,pin-con-pdn = <3>;
		samsung,pin-pud-pdn = <0>;
	};

	nfc_en: nfc_en {
		samsung,pins = "gpg0-0";
		samsung,pin-function = <0>;
		samsung,pin-pud = <0>;
		samsung,pin-drv = <0>;
		samsung,pin-con-pdn = <3>;
		samsung,pin-pud-pdn = <0>;
	};
};

/* USI_2_CMGP */
&hsi2c_6 {
	#address-cells = <1>;
	#size-cells = <0>;
	gpios = <&gpm9 0 0 &gpm8 0 0>;
	status = "okay";
	clock-frequency = <400000>;
	samsung,reset-before-trans;
	sec-nfc@27 {
		compatible = "sec-nfc";
		reg = <0x27>;

		interrupts = <0 0 0>;
		interrupt-parent = <&gpa1>;

		sec-nfc,ven-gpio = <&gpg0 0 0>;
		sec-nfc,firm-gpio = <&gpg1 0 1>;
		sec-nfc,irq-gpio = <&gpa1 0 0>;
		sec-nfc,clk_req-gpio = <&gpg0 1 0xf>;
		sec-nfc,nfc_pvdd = "VDD_NFC_1P8";
		sec-nfc,clk_use = <2>;

		clocks = <&clock OSC_NFC>;
		clock-names = "oscclk_nfc";
		sec-nfc,nfc_ap_clk;
		sec-nfc,ldo_control;

		pinctrl-names = "default";
		pinctrl-0 = <&nfc_en &nfc_firm &xclkout1>;
	};
};

&pinctrl_4 {
	spi6_bus_suspend: spi6-bus-suspend {
		samsung,pins = "gpp2-0", "gpp2-1", "gpp2-2";
		samsung,pin-function = <0>;	/* INPUT */
		samsung,pin-pud = <1>;		/* DOWN */
		samsung,pin-drv = <0>;
	};
	spi6_cs_suspend: spi6-cs-suspend {
		samsung,pins = "gpp2-3";
		samsung,pin-function = <0>;	/* INPUT */
		samsung,pin-pud = <1>;		/* DOWN */
		samsung,pin-drv = <0>;
	};
};

&spi_6 {
	status = "okay";
	/delete-property/ pinctrl-names;
	/delete-property/ pinctrl-0;
	pinctrl-names = "ese_active", "ese_suspend";
	pinctrl-0 = <&spi6_bus &spi6_cs>;
	pinctrl-1 = <&spi6_bus_suspend &spi6_cs_suspend>;

	ese_spi@0 {
		compatible = "ese_p3";
		reg = <0>;
		spi-max-frequency = <13000000>;
		gpio-controller;
		#gpio-cells = <2>;
		p3-vdd_1p8-gpio = <&gpg0 4 1>;

		clocks = <&clock GATE_SPI_0_QCH>, <&clock SPI0>;
		clock-names = "pclk", "sclk";
		ese_p3,cs-gpio = <&gpp2 1 0>;

		controller-data {
			samsung,spi-feedback-delay = <0>;
			samsung,spi-chip-select-mode = <0>;
		};
	};
};

&i2c_0 {
	i2c-gpio,delay-us = <5>;
	status = "okay";
	samsung,glitch-filter;
	samsung,fix-doxfer-return;
	#address-cells = <1>;
	#size-cells = <0>;
	usbpd-5713@33 {
		compatible = "sm5713-usbpd,i2c";
		reg = <0x33>;
		pinctrl-names = "default";
		vconn-en;
		support_pd_role_swap;
		pinctrl-0 = <&usbpd_irq>;
		usbpd,usbpd_int = <&gpa2 3 0>;
	};
};

&i2c_1 {
	#address-cells = <1>;
	#size-cells = <0>;
	status = "okay";
	samsung,glitch-filter;
	samsung,fix-doxfer-return;
	sm5713@49{
		compatible = "siliconmitus,sm5713mfd";
		reg = <0x49>;
		pinctrl-names = "default";
		pinctrl-0 = <&chg_en &if_pmic_irq>;
		sm5713,irq-gpio = <&gpa2 2 0>;
		sm5713,wakeup;
	};
};


&hsi2c_3 {
	#address-cells = <1>;
	#size-cells = <0>;
	status = "okay";
	tfa98xx: tfa98xx@34 {
		compatible = "nxp,tfa98xx";
		#sound-dai-cells = <1>;
		reg = <0x34>;
	};
};

&i2c_5 {
	status = "okay";
	#address-cells = <1>;
	#size-cells = <0>;
	samsung,i2c-sda-delay = <100>;
	samsung,i2c-max-bus-freq = <400000>;
	pinctrl-names = "default";
	pinctrl-0 = <&grip_i2c>;

	a96t3x6@20 {
		compatible = "a96t3x6";
		pinctrl-names = "default", "grip_ldo";
		pinctrl-0 = <&grip_int &grip_ldo>;
		reg = <0x20>;
		interrupt-parent = <&gpa2>;
		interrupts = <7 0 0>;
		a96t3x6,irq_gpio = <&gpa2 7 0>;
		a96t3x6,ldo_en = <&gpg2 1 0>;
		/* temporary firmware */
		a96t3x6,fw_path = "abov/a96t326_voguelte.fw";
		a96t3x6,firmup_cmd = <0x32>;
	};
};
